# PRUSS1_CFG register map
Vendor: Texas Instruments
Peripheral module from a debugger description file (folder DRA72x).
Registers are 32-bit, access per field, reset 0x0 unless marked. A register's access mark holds for its fields unless they carry their own. Offsets are as the file gives them; lines under a group give offsets from that group; [hi:lo] are bit positions; {n}, {i} and the like mark numbered series; 'fields as' and 'values as' point back to an identical list; <NAME> marks a mode.

## PRUSS1_CFG
0x00 PRUSS_REVID ro reset not defined — The Revision Register contains the ID and revision information.
  [31:0] REVISION — IP Revision
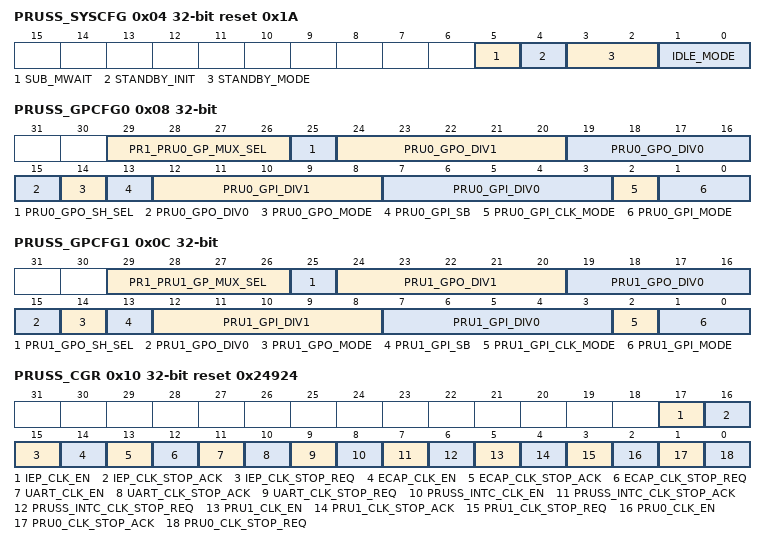
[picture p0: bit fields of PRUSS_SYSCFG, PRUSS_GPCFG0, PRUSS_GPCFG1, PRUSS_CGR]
0x04 PRUSS_SYSCFG reset 0x1A — The System Configuration Register defines the power IDLE and STANDBY modes.
  [5] SUB_MWAIT ro — Status bit for wait state. 0x0 = Ready for Transaction 0x1 = Wait until 0
  [4] STANDBY_INIT rw — 0x1 = Initiate standby sequence. 0x0 = Enable OCP master ports.
  [3:2] STANDBY_MODE rw — 0x0 = Force standby mode: Initiator unconditionally in standby (standby = 1) 0x1 = No standby mode: Initiator unconditionally out of standby (standby = 0) 0x2 = Smart standby mode: Standby requested by initiator depending on internal conditions 0x3 = Reserved
  [1:0] IDLE_MODE rw — 0x0 = Force-idle mode 0x1 = No-idle mode 0x2 = Smart-idle mode 0x3 = Reserved
0x08 PRUSS_GPCFG0 — The General Purpose Configuration 0 Register defines the GPIO configuration for PRU0.
  [29:26] PR1_PRU0_GP_MUX_SEL rw — Controls the icss_wrap mux select 0000: GP selected 0001: EnDAT mode 0010: Reserved 0011: SD mode 0100: MII2 mode Note: SD mode is not supported on this device.
  [25] PRU0_GPO_SH_SEL ro — Defines which shadow register is currently getting used for GPO shifting. 0x0 = gpo_sh0 is selected 0x1 = gpo_sh1 is selected
  [24:20] PRU0_GPO_DIV1 rw — Divisor value (divide by PRU0_GPO_DIV1 + 1). 0x00 = div 1.0 0x01 = div 1.5 0x02 = div 2.0 .. 0x1e = div 16.0 0x1f = reserved
  [19:15] PRU0_GPO_DIV0 rw — Divisor value (divide by PRU0_GPO_DIV0 + 1). 0x00 = div 1.0 0x01 = div 1.5 0x02 = div 2.0 .. 0x1e = div 16.0 0x1f = reserved
  [14] PRU0_GPO_MODE rw — 0x0 = Direct output mode 0x1 = Serial output mode
  [13] PRU0_GPI_SB rw — Start Bit event for 28-bit shift mode. PRU0_GPI_SB (pru0_r31_status[29]) is set when first capture of a 1 on pru0_r31_status[0]. Read 1: Start Bit event occurred. Read 0: Start Bit event has not occurred. Write 1: Will clear PRU0_GPI_SB and clear the whole shift register. Write 0: No Effect.
  [12:8] PRU0_GPI_DIV1 rw — Divisor value (divide by PRU0_GPI_DIV1 + 1). 0x00 = div 1.0 0x01 = div 1.5 0x02 = div 2.0 .. 0x1e = div 16.0 0x1f = reserved
  [7:3] PRU0_GPI_DIV0 rw — Divisor value (divide by PRU0_GPI_DIV0 + 1). 0x00 = div 1.0 0x01 = div 1.5 0x02 = div 2.0 .. 0x1e = div 16.0 0x1f = reserved
  [2] PRU0_GPI_CLK_MODE rw — Parallel 16-bit capture mode clock edge. 0x0 = Use the positive edge of pru0_r31_status[16] 0x1 = Use the negative edge of pru0_r31_status[16]
  [1:0] PRU0_GPI_MODE rw — 0x0 = Direct input mode 0x1 = 16-bit parallel capture mode 0x2 = 28-bit shift mode 0x3 = MII_RT mode
0x0C PRUSS_GPCFG1 — The General Purpose Configuration 1 Register defines the GPI O configuration for PRU1.
  [29:26] PR1_PRU1_GP_MUX_SEL rw — Controls the icss_wrap mux select 0000: GP selected 0001: EnDAT mode 0010: Reserved 0011: SD mode 0100: MII2 mode Note: SD mode is not supported on this device.
  [25] PRU1_GPO_SH_SEL ro — Defines which shadow register is currently getting used for GPO shifting. 0x0 = gpo_sh0 is selected 0x1 = gpo_sh1 is selected
  [24:20] PRU1_GPO_DIV1 rw — Divisor value (divide by PRU1_GPO_DIV1 + 1). 0x00 = div 1.0 0x01 = div 1.5 0x02 = div 2.0 .. 0x1e = div 16.0 0x1f = reserved
  [19:15] PRU1_GPO_DIV0 rw — Divisor value (divide by PRU1_GPO_DIV0 + 1). 0x00 = div 1.0 0x01 = div 1.5 0x02 = div 2.0 .. 0x1e = div 16.0 0x1f = reserved
  [14] PRU1_GPO_MODE rw — 0x0 = Direct output mode 0x1 = Serial output mode
  [13] PRU1_GPI_SB rw — 28-bit shift mode Start Bit event. PRU1_GPI_SB (pru1_r31_status[29]) is set when first capture of a 1 on pru1_r31_status[0]. Read 1: Start Bit event occurred. Read 0: Start Bit event has not occurred. Write 1: Will clear PRU1_GPI_SB and clear the whole shift register. Write 0: No Effect.
  [12:8] PRU1_GPI_DIV1 rw — Divisor value (divide by PRU1_GPI_DIV1 + 1). 0x00 = div 1.0 0x01 = div 1.5 0x02 = div 2.0 .. 0x1e = div 16.0 0x1f = reserved
  [7:3] PRU1_GPI_DIV0 rw — Divisor value (divide by PRU1_GPI_DIV0 + 1). 0x00 = div 1.0 0x01 = div 1.5 0x02 = div 2.0 .. 0x1e = div 16.0 0x1f = reserved
  [2] PRU1_GPI_CLK_MODE rw — Parallel 16-bit capture mode clock edge. 0x0 = Use the positive edge of pru1_r31_status[16] 0x1 = Use the negative edge of pru1_r31_status[16]
  [1:0] PRU1_GPI_MODE rw — 0x0 = Direct input mode 0x1 = 16-bit parallel capture mode 0x2 = 28-bit shift mode 0x3 = MII_RT mode
0x10 PRUSS_CGR reset 0x24924 — The Clock Gating Register controls the state of Clock Management of the different modules. Software should not clear {module}_CLK_EN until {module}_CLK_STOP_ACK is 0x1. Note: UART is not supported for both PRU-ICSS1 and PRU-ICSS2 on the DRA72x family of devices. Note: IEP and ECAP are not supported for PRU-ICSS2 on the DRA72x family of devices.
  [17] IEP_CLK_EN rw — IEP clock enable. 0x0 = Disable Clock 0x1 = Enable Clock
  [16] IEP_CLK_STOP_ACK ro — Acknowledgement that IEP clock can be stopped. 0x0 = Not Ready to Gate Clock 0x1 = Ready to Gate Clock
  [15] IEP_CLK_STOP_REQ rw — IEP request to stop clock. 0x0 = do not request to stop Clock 0x1 = request to stop Clock
  [14] ECAP_CLK_EN rw — ECAP clock enable. 0x0 = Disable Clock 0x1 = Enable Clock
  [13] ECAP_CLK_STOP_ACK ro — Acknowledgement that ECAP clock can be stopped. 0x0 = Not Ready to Gate Clock 0x1 = Ready to Gate Clock
  [12] ECAP_CLK_STOP_REQ rw — ECAP request to stop clock. 0x0 = do not request to stop Clock 0x1 = request to stop Clock
  [11] UART_CLK_EN rw — UART clock enable. 0x0 = Disable Clock 0x1 = Enable Clock
  [10] UART_CLK_STOP_ACK ro — Acknowledgement that UART clock can be stopped. 0x0 = Not Ready to Gate Clock 0x1 = Ready to Gate Clock
  [9] UART_CLK_STOP_REQ rw — UART request to stop clock. 0x0 = do not request to stop Clock 0x1 = request to stop Clock
  [8] PRUSS_INTC_CLK_EN rw — PRUSS_INTC clock enable. 0x0 = Disable Clock 0x1 = Enable Clock
  [7] PRUSS_INTC_CLK_STOP_ACK ro — Acknowledgement that PRUSS_INTC clock can be stopped. 0x0 = Not Ready to Gate Clock 0x1 = Ready to Gate Clock
  [6] PRUSS_INTC_CLK_STOP_REQ rw — PRUSS_INTC request to stop clock. 0x0 = do not request to stop Clock 0x1 = request to stop Clock
  [5] PRU1_CLK_EN rw — PRU1 clock enable. 0x0 = Disable Clock 0x1 = Enable Clock
  [4] PRU1_CLK_STOP_ACK ro — Acknowledgement that PRU1 clock can be stopped. 0x0 = Not Ready to Gate Clock 0x1 = Ready to Gate Clock
  [3] PRU1_CLK_STOP_REQ rw — PRU1 request to stop clock. 0x0 = do not request to stop Clock 0x1 = request to stop Clock
  [2] PRU0_CLK_EN rw — PRU0 clock enable. 0x0 = Disable Clock 0x1 = Enable Clock
  [1] PRU0_CLK_STOP_ACK ro — Acknowledgement that PRU0 clock can be stopped. 0x0 = Not Ready to Gate Clock 0x1 = Ready to Gate Clock
  [0] PRU0_CLK_STOP_REQ rw — PRU0 request to stop clock. 0x0 = do not request to stop Clock 0x1 = request to stop Clock
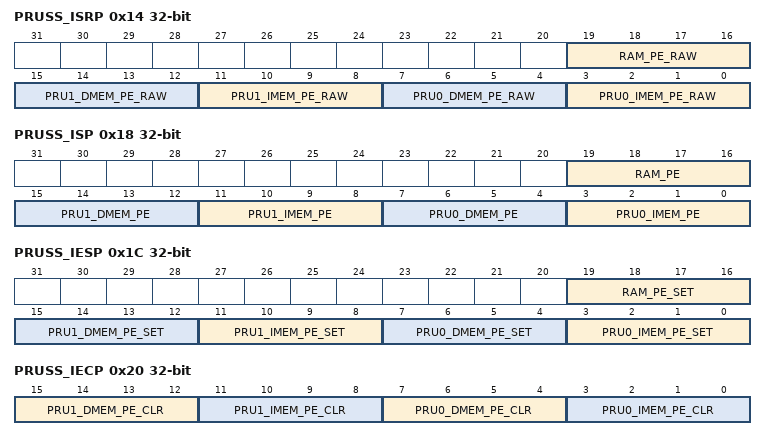
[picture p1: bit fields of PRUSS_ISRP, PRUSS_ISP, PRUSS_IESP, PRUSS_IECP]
0x14 PRUSS_ISRP — The IRQ Status Raw Parity register is a snapshot of the IRQ raw status for the PRUSS memory parity events. The raw status is set even if the event is not enabled.
  [19:16] RAM_PE_RAW rw — RAM Parity Error RAW for Byte3, Byte2, Byte1, Byte0. Note RAM_PE_RAW[0] maps to Byte0. Write 0: No action. Read 0: No event pending. Read 1: Event pending. Write 1: Set event (debug).
  [15:12] PRU1_DMEM_PE_RAW rw — PRU1 DMEM Parity Error RAW for Byte3, Byte2, Byte1, Byte0. Note PRU1_DMEM_PE_RAW[0] maps to Byte0. Write 0: No action. Read 0: No event pending. Read 1: Event pending. Write 1: Set event (debug).
  [11:8] PRU1_IMEM_PE_RAW rw — PRU1 IMEM Parity Error RAW for Byte3, Byte2, Byte1, Byte0. Note PRU1_IMEM_PE_RAW[0] maps to Byte0. Write 0: No action. Read 0: No event pending. Read 1: Event pending. Write 1: Set event (debug).
  [7:4] PRU0_DMEM_PE_RAW rw — PRU0 DMEM Parity Error RAW for Byte3, Byte2, Byte1, Byte0. Note PRU0_DMEM_PE_RAW[0] maps to Byte0. Write 0: No action. Read 0: No event pending. Read 1: Event pending. Write 1: Set event (debug) .
  [3:0] PRU0_IMEM_PE_RAW rw — PRU0 IMEM Parity Error RAW for Byte3, Byte2, Byte1, Byte0. Note PRU0_IRAM_PE_RAW[0] maps to Byte0. Write 0: No action. Read 0: No event pending. Read 1: Event pending. Write 1: Set event (debug) .
0x18 PRUSS_ISP — The IRQ Status Parity Register is a snapshot of the IRQ status for the PRUSS memory parity events. The status is set only if the event is enabled. Write 1 to clear the status after the interrupt has been serviced.
  [19:16] RAM_PE rw — RAM Parity Error for Byte3, Byte2, Byte1, Byte0. Note RAM_PE[0] maps to Byte0. Write 0: No action. Read 0: No (enabled) event pending. Read 1: Event pending. Write 1: Clear event.
  [15:12] PRU1_DMEM_PE rw — PRU1 DMEM Parity Error for Byte3, Byte2, Byte1, Byte0. Note PRU1_DMEM_PE[0] maps to Byte0. Write 0: No action. Read 0: No (enabled) event pending. Read 1: Event pending. Write 1: Clear event.
  [11:8] PRU1_IMEM_PE rw — PRU1 IMEM Parity Error for Byte3, Byte2, Byte1, Byte0. Note PRU1_IMEM_PE[0] maps to Byte0. Write 0: No action. Read 0: No (enabled) event pending. Read 1: Event pending. Write 1: Clear event.
  [7:4] PRU0_DMEM_PE rw — PRU0 DMEM Parity Error for Byte3, Byte2, Byte1, Byte0. Note PRU0_DMEM_PE[0] maps to Byte0. Write 0: No action. Read 0: No(enabled) event pending. Read 1: Event pending. Write 1: Clear event.
  [3:0] PRU0_IMEM_PE rw — PRU0 IMEM Parity Error for Byte3, Byte2, Byte1, Byte0. Note PRU0_IMEM_PE[0] maps to Byte0. Write 0: No action. Read 0: No (enabled) event pending. Read 1: Event pending. Write 1: Clear event.
0x1C PRUSS_IESP — The IRQ Enable Set Parity Register enables the IRQ PRUSS memory parity events.
  [19:16] RAM_PE_SET rw — RAM Parity Error Set Enable for Byte3, Byte2, Byte1, Byte0. Note RAM_PE_SET[0] maps to Byte0. Write 0: No action. Read 0: Interrupt disabled (masked). Read 1: Interrupt enabled. Write 1: Enable interrupt.
  [15:12] PRU1_DMEM_PE_SET rw — PRU1 DMEM Parity Error Set Enable for Byte3, Byte2, Byte1, Byte0. Note PRU1_DMEM_PE_SET[0] maps to Byte0. Write 0: No action. Read 0: Interrupt disabled (masked). Read 1: Interrupt enabled. Write 1: Enable interrupt.
  [11:8] PRU1_IMEM_PE_SET rw — PRU1 IMEM Parity Error Set Enable for Byte3, Byte2, Byte1, Byte0. Note PRU1_IMEM_PE_SET[0] maps to Byte0. Write 0: No action. Read 0: Interrupt disabled (masked). Read 1: Interrupt enabled. Write 1: Enable interrupt.
  [7:4] PRU0_DMEM_PE_SET rw — PRU0 DMEM Parity Error Set Enable for Byte3, Byte2, Byte1, Byte0. Note PRU0_DMEM_PE_SET[0] maps to Byte0. Write 0: No action. Read 0: Interrupt disabled (masked). Read 1: Interrupt enabled. Write 1: Enable interrupt.
  [3:0] PRU0_IMEM_PE_SET rw — PRU0 IMEM Parity Error Set Enable for Byte3, Byte2, Byte1, Byte0. Note PRU0_IMEM_PE_SET[0] maps to Byte0. Write 0: No action. Read 0: Interrupt disabled (masked). Read 1: Interrupt enabled. Write 1: Enable interrupt.
0x20 PRUSS_IECP — The IRQ Enable Clear Parity Register disables the IRQ PRUSS memory parity events.
  [15:12] PRU1_DMEM_PE_CLR rw — PRU1 DMEM Parity Error Clear Enable for Byte3, Byte2, Byte1, Byte0. Note PRU1_DMEM_PE_CLR[0] maps to Byte0. Write 0: No action. Read 0: Interrupt disabled (masked). Read 1: Interrupt enabled. Write 1: Disable interrupt.
  [11:8] PRU1_IMEM_PE_CLR rw — PRU1 IMEM Parity Error Clear Enable for Byte3, Byte2, Byte1, Byte0. Note PRU1_IMEM_PE_CLR[0] maps to Byte0. Write 0: No action. Read 0: Interrupt disabled (masked). Read 1: Interrupt enabled. Write 1: Disable interrupt.
  [7:4] PRU0_DMEM_PE_CLR rw — PRU0 DMEM Parity Error Clear Enable for Byte3, Byte2, Byte1, Byte0. Note PRU0_DMEM_PE_CLR[0] maps to Byte0. Write 0: No action. Read 0: Interrupt disabled (masked). Read 1: Interrupt enabled. Write 1: Disable interrupt.
  [3:0] PRU0_IMEM_PE_CLR rw — PRU0 IMEM Parity Error Clear Enable for Byte3, Byte2, Byte1, Byte0. Note PRU0_IMEM_PE_CLR[0] maps to Byte0. Write 0: No action . Read 0: Interrupt disabled (masked). Read 1: Interrupt enabled. Write 1: Disable interrupt.
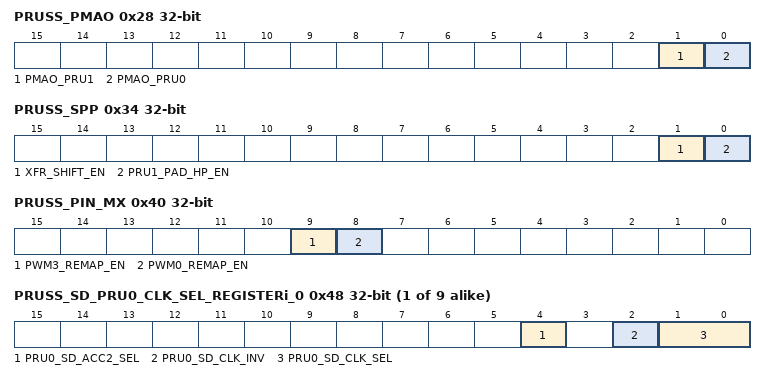
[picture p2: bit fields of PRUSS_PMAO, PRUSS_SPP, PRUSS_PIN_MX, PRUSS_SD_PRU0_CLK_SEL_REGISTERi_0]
0x28 PRUSS_PMAO — The PRU Master OCP Address Offset Register enables for the PRU OCP Master Port Address to have an offset of minus 0x0008_0000. This enables the PRU to access External Host address space starting at 0x0000_0000.
  [1] PMAO_PRU1 rw — PRU1 OCP Master Port Address Offset Enable. 0x0 = Disable address offset. 0x1 = Enable address offset of -0x0008_0000.
  [0] PMAO_PRU0 rw — PRU0 OCP Master Port Address Offset Enable. 0x0 = Disable address offset. 0x1 = Enable address offset of -0x0008_0000.
0x2C PRUSS_MII_RT — The MII_RT Event Enable Register enables MII_RT mode events to the PRUSS.PRUSS_INTC.
  [0] OCP_EN rw — IEP clock source 0x0 = IEP_CLK is the source 0x1 = ICLK is the source. While this is selected no transactions should be active. It can only be cleared by a hardware reset.
0x30 PRUSS_IEPCLK — The IEP Clock Source Register defines the source of the IEP clock.
  fields as PRUSS_MII_RT
0x34 PRUSS_SPP — The Scratch Pad Priority and Configuration Register defines the access priority assigned to the PRU cores and configures the scratch pad XFR shift functionality.
  [1] XFR_SHIFT_EN rw — Enables XIN XOUT shift functionality. When enabled, R0[4:0] (internal to PRU) defines the 32-bit offset for XIN and XOUT operations with the scratch pad. 0x0 = Disabled. 0x1 = Enabled.
  [0] PRU1_PAD_HP_EN rw — Defines which PRU wins write cycle arbitration to a common scratch pad bank. The PRU which has higher priority will always perform the write cycle with no wait states. The lower PRU will get stalled wait states until higher PRU is not performing write cycles. If the lower priority PRU writes to the same byte has the higher priority PRU, then the lower priority PRU will over write the bytes. 0x0 = PRU0 has highest priority. 0x1 = PRU1 has highest priority.
0x40 PRUSS_PIN_MX — The Pin Mux Select Register defines the state of the PRUSS internal pinmuxing.
  [9] PWM3_REMAP_EN rw — UNUSED IN THIS DEVICE
  [8] PWM0_REMAP_EN rw — If enabled, host intr6 of PRUSS2 controls epwm_sync_in of PWMSS1 instead of ehrpwm1_synci device pin
{0x48+8i} PRUSS_SD_PRU0_CLK_SEL_REGISTERi_{i} (i=0..8) — SD acc and clock select Sigma-delta (SD) mode is not supported on this device.
  [4] PRU0_SD_ACC2_SEL rw — acc3/acc2 mux 0: acc3 is selected 1: acc2 is selected
  [2] PRU0_SD_CLK_INV rw — Optional clock inversion post clock selection mux 0 = No inversion 1 = Inversion
  [1:0] PRU0_SD_CLK_SEL rw — Selects the clock source 0x0: pr1/2_pru0_gpi[16] 0x1: pr1/2_pru0_sdi_clk 0x2: pr1/2_pru0_sd0_clk for sd0, sd1, and sd2; pr1/2_pru0_sd3_clk for sd3, sd4, and sd5; pr1/2_pru0_sd6_clk for sd6, sd7, and sd8 0x3: reserved
{0x4C+8i} PRUSS_SD_PRU0_SAMPLE_SIZE_REGISTERi_{i} reset 0x7 (i=0..8) — SD oversample size Sigma-delta (SD) mode is not supported on this device.
  [7:0] PRU0_SD_SAMPLE_SIZE rw — SD Sample Size. This field defines the sample size window to latch selected accumulator. 0 = Reserved 1 = Reserved 2 = Reserved 3 = 4 samples 4 = 5 samples 5 = 6 samples 6 = 7 samples 7 = 8 samples N = N+1 samples Max value (N) may be capped by number of bits supported by accumulator. Note this value is only loaded into a shadow copy when channel_en is 0 OR re_init is asserted.
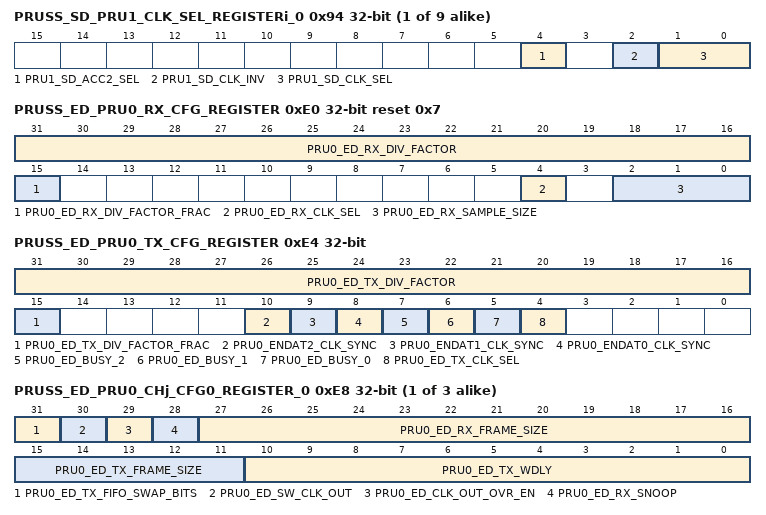
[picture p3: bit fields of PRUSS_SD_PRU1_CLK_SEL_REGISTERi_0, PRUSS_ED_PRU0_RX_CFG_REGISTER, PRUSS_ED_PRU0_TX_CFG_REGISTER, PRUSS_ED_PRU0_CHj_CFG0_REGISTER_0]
{0x94+8i} PRUSS_SD_PRU1_CLK_SEL_REGISTERi_{i} (i=0..8) — SD acc and clock select Sigma-delta (SD) mode is not supported on this device.
  [4] PRU1_SD_ACC2_SEL rw — acc3/acc2 mux 0: acc3 is selected 1: acc2 is selected
  [2] PRU1_SD_CLK_INV rw — Optional clock inversion post clock selection mux 0 = No inversion 1 = Inversion
  [1:0] PRU1_SD_CLK_SEL rw — Selects the clock source 0x0: pr1/2_pru1_gpi[16] 0x1: pr1/2_pru1_sdi_clk 0x2: pr1/2_pru1_sd0_clk for sd0, sd1, and sd2; pr1/2_pru1_sd3_clk for sd3, sd4, and sd5; pr1/2_pru1_sd6_clk for sd6, sd7, and sd8 0x3: reserved
{0x98+8i} PRUSS_SD_PRU1_SAMPLE_SIZE_REGISTERi_{i} reset 0x7 (i=0..8) — SD oversample size Sigma-delta (SD) mode is not supported on this device.
  [7:0] PRU1_SD_SAMPLE_SIZE rw — SD Sample Size. This field defines the sample size window to latch selected accumulator. 0 = Reserved 1 = Reserved 2 = Reserved 3 = 4 samples 4 = 5 samples 5 = 6 samples 6 = 7 samples 7 = 8 samples N = N+1 samples Max value (N) may be capped by number of bits supported by accumulator. Note this value is only loaded into a shadow copy when channel_en is 0 OR re_init is asserted.
0xE0 PRUSS_ED_PRU0_RX_CFG_REGISTER reset 0x7 — Endat Rx Config
  [31:16] PRU0_ED_RX_DIV_FACTOR rw — Division factor for divh16. Effective value is PRU0_ED_RX_DIV_FACTOR + 1. 0 = Div 1 1 = Div 2 N = Div (N+1)
  [15] PRU0_ED_RX_DIV_FACTOR_FRAC rw — Enable Fractional division before the divh16. 0: div 1 1: div 1.5
  [4] PRU0_ED_RX_CLK_SEL rw — Selects the clock source for the divh16fr. 0: 192 MHz UART_CLK 1: 200MHz ICLK
  [2:0] PRU0_ED_RX_SAMPLE_SIZE rw — Over Sample size. This field defines the number of samples before the shadow copy gets updated and the VAL flag gets set. The effective count is (RX_SAMPLE_SIZE + 1). 0 = Reserved 1 = Reserved 2 = Reserved 3 = Over Sample of 4 4 = Over Sample of 5 5 = Over Sample of 6 6 = Over Sample of 7 7 = Over Sample of 8 Note the Over Sample Clock rate divided by the TX Clock rate must equal the Over Sample size.
0xE4 PRUSS_ED_PRU0_TX_CFG_REGISTER — Endat Tx Config
  [31:16] PRU0_ED_TX_DIV_FACTOR rw — Division factor for divh16. Effective value is PRU0_ED_TX_DIV_FACTOR + 1. 0 = Div 1 1 = Div 2 N = Div (N+1)
  [15] PRU0_ED_TX_DIV_FACTOR_FRAC rw — Enable Fractional division before the divh16. 0: div1 1: div 1.5
  [10] PRU0_ENDAT2_CLK_SYNC ro — Observation of pr1/2_pru0_endat2_clk pin. Note this is part of the Peripheral Interface configuration settings. The usage of this signal is not restricted to only ENDAT interfaces.
  [9] PRU0_ENDAT1_CLK_SYNC ro — Observation of pr1/2_pru0_endat1_clk pin. Note this is part of the Peripheral Interface configuration settings. The usage of this signal is not restricted to only ENDAT interfaces.
  [8] PRU0_ENDAT0_CLK_SYNC ro — Observation of pr1/2_pru0_endat0_clk pin. Note this is part of the Peripheral Interface configuration settings. The usage of this signal is not restricted to only ENDAT interfaces.
  [7] PRU0_ED_BUSY_2 ro — Determines when is allowed to assert tx go for channel 2. 0: ready to go 1: busy
  [6] PRU0_ED_BUSY_1 ro — Determines when is allowed to assert tx go for channel 1. 0: ready to gob 1: busy
  [5] PRU0_ED_BUSY_0 ro — Determines when is allowed to assert tx go for channel 0. 0: ready to go 1: busy
  [4] PRU0_ED_TX_CLK_SEL rw — Selects the clock source for the divh16fr. 0: 192 MHz UART_CLK 1: 200MHz ICLK
{0xE8+8i} PRUSS_ED_PRU0_CHj_CFG0_REGISTER_{i} (i=0..2) — Endat Channel j Config 0 register
  [31] PRU0_ED_TX_FIFO_SWAP_BITS rw — Enables the swapping of the bits when they are loaded into the TX FIFO. 0: no swap 1: swap [7:0] -&gt; [0:7] NOTE: FIFO MSB always exports bit [7] first.
  [30] PRU0_ED_SW_CLK_OUT rw — This controls the state of pr1/2_pru0_endatj_clk pin when PRU0_ED_CLK_OUT_OVR_EN is set. Note this is part of the Peripheral Interface configuration settings. The usage of this signal is not restricted to only ENDAT interfaces.
  [29] PRU0_ED_CLK_OUT_OVR_EN rw — When set, enables the software to control pr1/2_pru0_endatj_clk pin. WARNING: Do not override clock during free running mode. This will cause clock duty cycle violation.
  [28] PRU0_ED_RX_SNOOP ro — Direct view of pr1/2_pru0_endatj_in pin. Note this is part of the Peripheral Interface configuration settings. The usage of this signal is not restricted to only ENDAT interfaces.
  [27:16] PRU0_ED_RX_FRAME_SIZE rw — RX frame size, after start bit is detected 0: = Special case for TX only phase, ignores start bit, in this case TX CLK_OUT will stop after last TX 1: = TX CLK_OUT will stop after 1 X Over Sample 8: = TX CLK_OUT will stop after 8 X Over Sample 9: = TX CLK_OUT will stop after 9 X Over Sample 4095 TX CLK_OUT will stop after 2047 X Over Sample Note X Over Sample means the number of VAL events. 1 VAL per Over Sample event. When the TX CLK_MODE[1:0] is either 0x0 or 0x1, when this RX_FRAME_SIZE is reached, the tx master CLK_OUT will remain high or low. WARNING: Software must not de-assert RX_EN before RX_FRAME_SIZE expires.
  [15:11] PRU0_ED_TX_FRAME_SIZE rw — TX frame size 0: disabled, the FIFO will transmit until empty then stop 1: TX FIFO will transmit 1 bits then stop 2: TX FIFO will transmit 2 bits then stop 31: TX FIFO will transmit 31 bits then stop Note: At TX completion, pr1/2_pru0_endatj_out_en will deassert.
  [10:0] PRU0_ED_TX_WDLY rw — EnDAT TX wire delay using 200-MHz steps (ICLK). Software must program a number divisible by 5. 0: = no delay 5: = 5 ns delay 10: = 10 ns delay 15: = 15 ns delay 2024 = 2.045 µs delay. This is used during TX state when CLK_OUT goes from high to low, this transmission can be compensated. Hardware will keep count of clocks and add 5 each time. Note the first rising edge of EnDAT CLK from a TX GO event is tx_wire_dly + tst_delay_counter + ½ EnDAT CLK period +/- 15ns. Note this is part of the Peripheral Interface configuration settings. The usage of this signal is not restricted to only ENDAT interfaces.
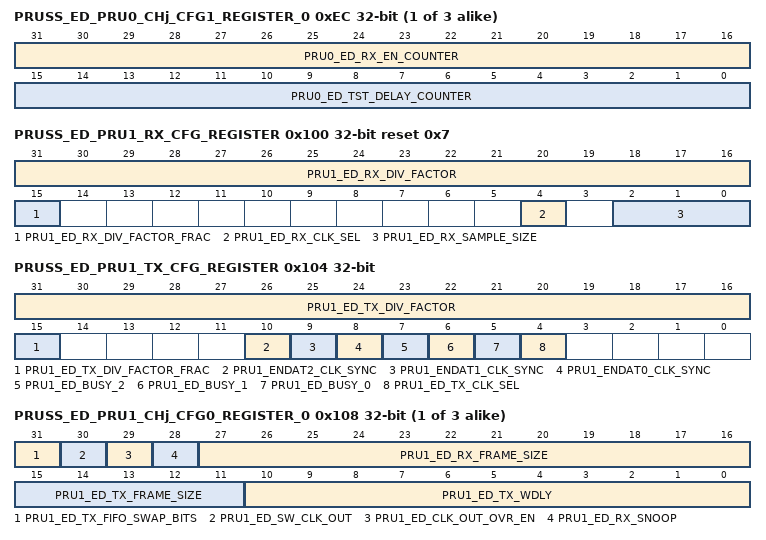
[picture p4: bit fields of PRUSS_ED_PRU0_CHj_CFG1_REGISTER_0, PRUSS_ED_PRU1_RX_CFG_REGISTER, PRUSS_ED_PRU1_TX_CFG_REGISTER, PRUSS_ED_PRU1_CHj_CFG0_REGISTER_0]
{0xEC+8i} PRUSS_ED_PRU0_CHj_CFG1_REGISTER_{i} rw (i=0..2) — Endat Channel j Config 1 register
  [31:16] PRU0_ED_RX_EN_COUNTER — This counter will start counting after the last TX bit is sent. When it expires, the HW will automatically arm the receiver (RX_EN = 1). Program to 0 if HW support is not desired. Counts in ICLK cycles. Software must program value in increments of 5 (hardware will count by 5s). For example 30, will be 6 ICLK cycles. All channels must be use this feature if enabled. The HW does not allow support of some channels with auto enable and others manual enable.
  [15:0] PRU0_ED_TST_DELAY_COUNTER — This counter will start after the tx_wire_delay has been met. After this counter expires the 1st transmit clock will be driven high. Counts in ICLK cycles. Software must program value divisible by 5, and hardware will count by 5. For example 30, will be 6 ICLK cycles. Note the first rising edge of EnDAT CLK from a TX GO event is tx_wire_dly + tst_delay_counter + ½ EnDAT CLK period +/- 15ns
0x100 PRUSS_ED_PRU1_RX_CFG_REGISTER reset 0x7 — Endat Rx Config
  [31:16] PRU1_ED_RX_DIV_FACTOR rw — Division factor for divh16. Effective value is PRU1_ED_RX_DIV_FACTOR + 1. 0 = Div 1 1 = Div 2 N = Div (N+1)
  [15] PRU1_ED_RX_DIV_FACTOR_FRAC rw — Enable Fractional division before the divh16. 0: div 1 1: div 1.5.
  [4] PRU1_ED_RX_CLK_SEL rw — Selects the clock source for the divh16fr. 0: 192 MHz UART_CLK 1: 200MHz ICLK
  [2:0] PRU1_ED_RX_SAMPLE_SIZE rw — Over Sample size. This field defines the number of samples before the shadow copy gets updated and the VAL flag gets set. The effective count is (RX_SAMPLE_SIZE + 1). 0 = Reserved 1 = Reserved 2 = Reserved 3 = Over Sample of 4 4 = Over Sample of 5 5 = Over Sample of 6 6 = Over Sample of 7 7 = Over Sample of 8 Note the Over Sample Clock rate divided by the TX Clock rate must equal the Over Sample size.
0x104 PRUSS_ED_PRU1_TX_CFG_REGISTER — Endat Tx Config
  [31:16] PRU1_ED_TX_DIV_FACTOR rw — Division factor for divh16. Effective value is PRU1_ED_TX_DIV_FACTOR + 1. 0 = Div 1 1 = Div 2 N = Div (N+1)
  [15] PRU1_ED_TX_DIV_FACTOR_FRAC rw — Enable Fractional division before the divh16. 0: div1 1: div 1.5
  [10] PRU1_ENDAT2_CLK_SYNC ro — Observation of pr1/2_pru1_endat2_clk pin. Note this is part of the Peripheral Interface configuration settings. The usage of this signal is not restricted to only ENDAT interfaces.
  [9] PRU1_ENDAT1_CLK_SYNC ro — Observation of pr1/2_pru1_endat1_clk pin. Note this is part of the Peripheral Interface configuration settings. The usage of this signal is not restricted to only ENDAT interfaces.
  [8] PRU1_ENDAT0_CLK_SYNC ro — Observation of pr1/2_pru1_endat0_clk pin. Note this is part of the Peripheral Interface configuration settings. The usage of this signal is not restricted to only ENDAT interfaces.
  [7] PRU1_ED_BUSY_2 ro — Determines when is allowed to assert tx go for channel 2. 0: ready to go 1: busy
  [6] PRU1_ED_BUSY_1 ro — Determines when is allowed to assert tx go for channel 1. 0: ready to go 1: busy
  [5] PRU1_ED_BUSY_0 ro — Determines when is allowed to assert tx go for channel 0. 0: ready to go 1: busy
  [4] PRU1_ED_TX_CLK_SEL rw — Selects the clock source for the divh16fr. 0: 192 MHz UART_CLK 1: 200MHz ICLK
{0x108+8i} PRUSS_ED_PRU1_CHj_CFG0_REGISTER_{i} (i=0..2) — Endat Channel j Config 0 register
  [31] PRU1_ED_TX_FIFO_SWAP_BITS rw — Enables the swapping of the bits when they are loaded into the TX FIFO. 0: no swap 1: swap [7:0] -&gt; [0:7] NOTE: FIFO MSB always exports bit [7] first.
  [30] PRU1_ED_SW_CLK_OUT rw — This controls the state of pr1/2_pru1_endatj_clk pin when PRU1_ED_CLK_OUT_OVR_EN is set. Note this is part of the Peripheral Interface configuration settings. The usage of this signal is not restricted to only ENDAT interfaces.
  [29] PRU1_ED_CLK_OUT_OVR_EN rw — When set, enables the software to control pr1/2_pru1_endatj_clk pin. WARNING: Do not override clock during free running mode. This will cause clock duty cycle violation.
  [28] PRU1_ED_RX_SNOOP ro — Direct view of pr1/2_pru1_endatj_in pin. Note this is part of the Peripheral Interface configuration settings. The usage of this signal is not restricted to only ENDAT interfaces.
  [27:16] PRU1_ED_RX_FRAME_SIZE rw — RX frame size, after start bit is detected 0: = Special case for TX only phase, ignores start bit, in this case TX CLK_OUT will stop after last TX 1: = tx_clk out will stop after 1 X Over Sample 8: = tx_clk out will stop after 8 X Over Sample 9: = tx_clk out will stop after 9 X Over Sample 4095 tx_clk out will stop after 2047 X Over Sample Note X Over Sample means the number of VAL events. 1 VAL per Over Sample event. When the TX CLK_MODE[1:0] is either 0x0 or 0x1, when this RX_FRAME_SIZE is reached, the tx master CLOCK_OUT will remain high or low. WARNING: Software must not de-assert RX_EN before RX_FRAME_SIZE expires.
  [15:11] PRU1_ED_TX_FRAME_SIZE rw — TX frame size 0: disabled, the FIFO will transmit until empty then stop 1: TX FIFO will transmit 1 bits then stop 2: TX FIFO will transmit 2 bits then stop . .. 31: TX FIFO will transmit 31 bits then stop Note: At TX completion, pr1/2_pru1_endatj_out_en will deassert.
  [10:0] PRU1_ED_TX_WDLY rw — EnDAT TX wire delay using 200-MHz steps (ICLK). Software must program a number divisible by 5. 0: = no delay 5: = 5 ns delay 10: = 10 ns delay 15: = 15 ns delay 2024 = 2.045 µs delay. This is used during TX state when CLK_OUT goes from high to low, this transmission can be compensated. Hardware will keep count of clocks and add 5 each time. Note the first rising edge of EnDAT CLK from a TX GO event is tx_wire_dly + tst_delay_counter + ½ EnDAT CLK period +/- 15ns . Note this is part of the Peripheral Interface configuration settings. The usage of this signal is not restricted to only ENDAT interfaces.
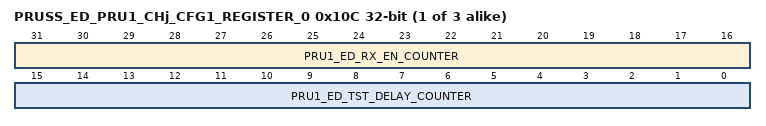
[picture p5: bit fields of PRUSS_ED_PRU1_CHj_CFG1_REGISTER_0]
{0x10C+8i} PRUSS_ED_PRU1_CHj_CFG1_REGISTER_{i} rw (i=0..2) — Endat Channel j Config 1 register
  [31:16] PRU1_ED_RX_EN_COUNTER — This counter will start counting after the last TX bit is sent. When it expires, the HW will automatically arm the receiver (RX_EN = 1). Program to 0 if HW support is not desired. Counts in ICLK cycles. Software must program value in increments of 5 (hardware will count by 5s). For example 30, will be 6 ICLK cycles. All channels must be use this feature if enabled. The HW does not allow support of some channels with auto enable and others manual enable.
  [15:0] PRU1_ED_TST_DELAY_COUNTER — This counter will start after the tx_wire_delay has been met. After this counter expires the 1st transmit clock will be driven high. Counts in ICLK cycles. Software must program value divisible by 5, and hardware will count by 5. For example 30, will be 6 ICLK cycles. Note the first rising edge of EnDAT CLK from a TX GO event is tx_wire_dly + tst_delay_counter + ½ EnDAT CLK period +/- 15ns
